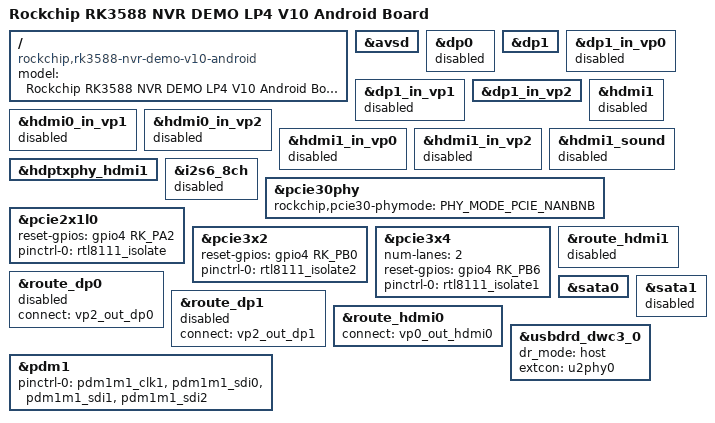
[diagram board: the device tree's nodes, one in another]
// SPDX-License-Identifier: (GPL-2.0+ OR MIT)
/*
 * Copyright (c) 2021 Rockchip Electronics Co., Ltd.
 *
 */

/dts-v1/;

#include "rk3588-nvr-demo.dtsi"
#include "rk3588-android.dtsi"

/ {
	model = "Rockchip RK3588 NVR DEMO LP4 V10 Android Board";
	compatible = "rockchip,rk3588-nvr-demo-v10-android", "rockchip,rk3588";
};

&avsd {
	status = "okay";
};

&dp0 {
	status = "disabled";
};

&dp1 {
	status = "okay";
};
&dp1_in_vp0 {
	status = "disabled";
};

&dp1_in_vp1 {
	status = "disabled";
};

&dp1_in_vp2 {
	status = "okay";
};
&hdmi0_in_vp1 {
	status = "disabled";
};

&hdmi0_in_vp2 {
	status = "disabled";
};

&hdmi1 {
	status = "disabled";
};

&hdmi1_in_vp0 {
	status = "disabled";
};

&hdmi1_in_vp2 {
	status = "disabled";
};

&hdmi1_sound {
	status = "disabled";
};

&hdptxphy_hdmi1 {
	status = "okay";
};

&i2s6_8ch {
	status = "disabled";
};

&pcie30phy {
	rockchip,pcie30-phymode = <PHY_MODE_PCIE_NANBNB>;
	status = "okay";
};

&pcie2x1l0 {
        reset-gpios = <&gpio4 RK_PA2 GPIO_ACTIVE_HIGH>;
        pinctrl-names = "default";
        pinctrl-0 = <&rtl8111_isolate>;
	status = "okay";

};
&pcie3x2 {
	reset-gpios = <&gpio4 RK_PB0 GPIO_ACTIVE_HIGH>;
        pinctrl-0 = <&rtl8111_isolate2>;
	status = "okay";

};

&pcie3x4 {
	num-lanes = <2>;
	reset-gpios = <&gpio4 RK_PB6 GPIO_ACTIVE_HIGH>;
	pinctrl-names = "default";
        pinctrl-0 = <&rtl8111_isolate1>;
	status = "okay";
};

&route_dp0 {
	status = "disabled";
	connect = <&vp2_out_dp0>;
	/delete-property/ force-output;
	/delete-node/ force_timing;
};

&route_dp1 {
	status = "disabled";
	connect = <&vp2_out_dp1>;
	/delete-property/ force-output;
	/delete-node/ force_timing;
};

&route_hdmi0 {
	status = "okay";
	connect = <&vp0_out_hdmi0>;
	/delete-property/ force-output;
	/delete-node/ force_timing;
};

&route_hdmi1 {
	status = "disabled";
};

&sata0 {
	status = "okay";
};

&sata1 {
	status = "disabled";
};
&pdm1{
       status = "okay";
       pinctrl-names = "default";
       pinctrl-0 = <&pdm1m1_clk1
                    &pdm1m1_sdi0
                    &pdm1m1_sdi1
                    &pdm1m1_sdi2>;

};
&usbdrd_dwc3_0 {
	dr_mode = "host";
	extcon = <&u2phy0>;
	status = "okay";
};
